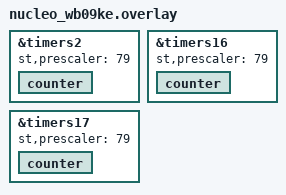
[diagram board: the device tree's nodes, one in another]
/*
 * Copyright (c) 2025 STMicroelectronics
 *
 * SPDX-License-Identifier: Apache-2.0
 */

&timers2 {
	st,prescaler = <79>;
	status = "okay";

	counter {
		status = "okay";
	};
};

&timers16 {
	st,prescaler = <79>;
	status = "okay";

	counter {
		status = "okay";
	};
};

&timers17 {
	st,prescaler = <79>;
	status = "okay";

	counter {
		status = "okay";
	};
};
